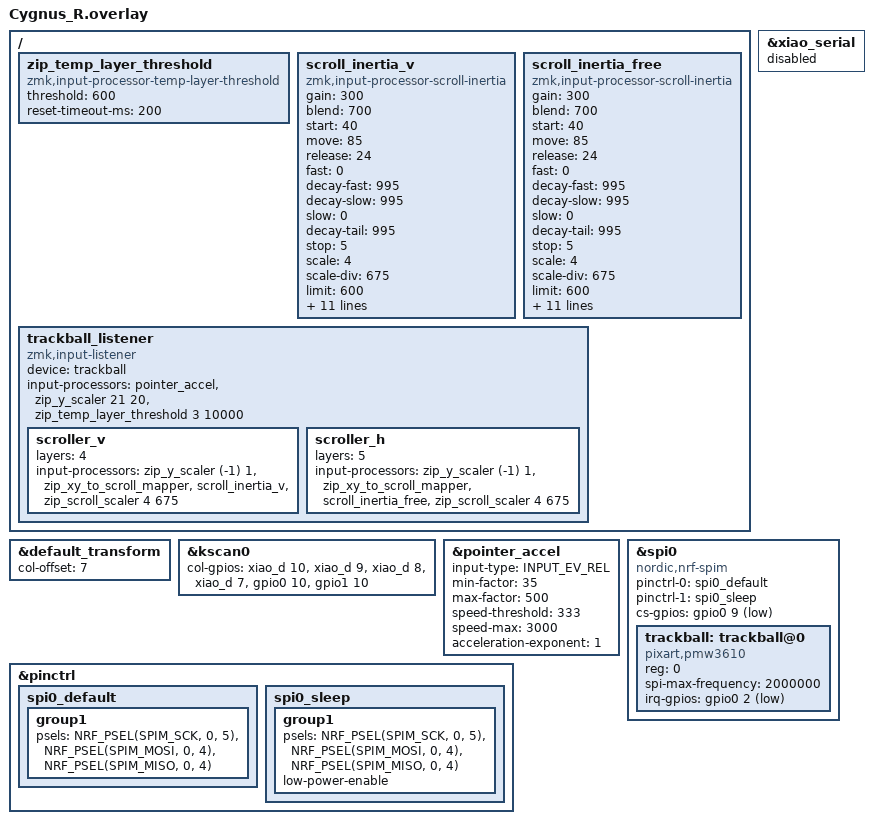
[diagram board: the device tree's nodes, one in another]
#include "Cygnus.dtsi"
#include <input/processors.dtsi>
#include <behaviors/input_gestures_accel.dtsi>
#include <dt-bindings/input/input-event-codes.h>
#include <dt-bindings/zmk/modifiers.h>

&default_transform {
    col-offset = <7>;
};

&kscan0 {
        col-gpios
            = <&xiao_d 10 GPIO_ACTIVE_HIGH>
            , <&xiao_d 9 GPIO_ACTIVE_HIGH>
            , <&xiao_d 8 GPIO_ACTIVE_HIGH>
            , <&xiao_d 7 GPIO_ACTIVE_HIGH>
            , <&gpio0 10 GPIO_ACTIVE_HIGH>
            , <&gpio1 10 GPIO_ACTIVE_HIGH>
            ;
};

/ {
    zip_temp_layer_threshold: zip_temp_layer_threshold {
        compatible = "zmk,input-processor-temp-layer-threshold";
        #input-processor-cells = <2>;
        threshold = <600>;         /* 約1/5回転 (25mm球, 1000CPI) */
        reset-timeout-ms = <200>;  /* 動きが止まったらカウントリセット */
    };

    scroll_inertia_v: scroll_inertia_v {
        compatible = "zmk,input-processor-scroll-inertia";
        #input-processor-cells = <0>;
        gain     = <300>;
        blend    = <700>;
        /* start    = <65>;          発動に必要な速度 */
        /* move     = <85>;         発動に必要な移動量 */
        start    = <40>;          /* 発動に必要な速度 */
        move     = <85>;         /* 発動に必要な移動量 */
        release  = <24>;
        fast     = <0>;
        decay-fast = <995>;
        decay-slow = <995>;
        slow     = <0>;          /* 低速区間に切替 */
        decay-tail = <995>;       /* 終端を更に緩やかに */
        stop     = <5>;           /* 離散化が目立たない閾値で停止 */
        scale    = <4>;
        scale-div = <675>;
        limit    = <600>;
        span     = <6000>;
        tick     = <4>;
        min-events = <20>;
        decel-samples = <6>;
        suppress-limit = <100>;
        peak-decay = <995>;
        axis     = <1>;
        layer    = <4>;
        friction = <10>;
        swap-mod = <(MOD_LSFT|MOD_RSFT)>;  /* Shiftで縦↔横入れ替え */
        unlock-mod = <MOD_LALT>;           /* 左Altで両軸フリー (2Dスクロール) */
    };

    scroll_inertia_free: scroll_inertia_free {
        compatible = "zmk,input-processor-scroll-inertia";
        #input-processor-cells = <0>;
        gain     = <300>;
        blend    = <700>;
        /* start    = <65>;          発動に必要な速度 */
        /* move     = <85>;         発動に必要な移動量*/
        start    = <40>;          /* 発動に必要な速度 */
        move     = <85>;         /* 発動に必要な移動量 */
        release  = <24>;
        fast     = <0>;
        decay-fast = <995>;
        decay-slow = <995>;
        slow     = <0>;          /* 低速区間に切替 */
        decay-tail = <995>;       /* 終端を更に緩やかに */
        stop     = <5>;
        scale    = <4>;
        scale-div = <675>;
        limit    = <600>;
        span     = <6000>;
        tick     = <4>;
        min-events = <20>;
        decel-samples = <6>;
        suppress-limit = <100>;
        peak-decay = <995>;
        axis     = <0>;
        layer    = <5>;
        friction = <10>;
        swap-mod = <(MOD_LSFT|MOD_RSFT)>;
        unlock-mod = <MOD_LALT>;
    };

    trackball_listener: trackball_listener {
        compatible = "zmk,input-listener";
        device = <&trackball>;
        input-processors = <
            &pointer_accel
            &zip_y_scaler 21 20
            &zip_temp_layer_threshold 3 10000
        >;

        scroller_v {
            layers = <4>;
            input-processors = <
                &zip_y_scaler (-1) 1
                &zip_xy_to_scroll_mapper
                &scroll_inertia_v
                &zip_scroll_scaler 4 675
            >;
        };

        scroller_h {
            layers = <5>;
            input-processors = <
                &zip_y_scaler (-1) 1
                &zip_xy_to_scroll_mapper
                &scroll_inertia_free
                &zip_scroll_scaler 4 675
            >;
        };
    };
};

&pointer_accel {
    input-type = <INPUT_EV_REL>;
    min-factor = <35>;             /* 開始速度: 初速を1/3に抑制 */
    max-factor = <500>;            /* 最大速度: 加速の勢いを緩める */
    speed-threshold = <333>;       /* 加速開始点 */
    speed-max = <3000>;            /* この速度で最大に到達 */
    acceleration-exponent = <1>;   /* 二次曲線 (低速は緩く、高速で伸びる) */
};

&xiao_serial { status = "disabled"; };

&pinctrl {
    spi0_default: spi0_default {
        group1 {
            psels = <NRF_PSEL(SPIM_SCK, 0, 5)>,
                <NRF_PSEL(SPIM_MOSI, 0, 4)>,
                <NRF_PSEL(SPIM_MISO, 0, 4)>;
        };
    };

    spi0_sleep: spi0_sleep {
        group1 {
            psels = <NRF_PSEL(SPIM_SCK, 0, 5)>,
                <NRF_PSEL(SPIM_MOSI, 0, 4)>,
                <NRF_PSEL(SPIM_MISO, 0, 4)>;
            low-power-enable;
        };
    };
};

&spi0 {
    status = "okay";
    compatible = "nordic,nrf-spim";
    pinctrl-0 = <&spi0_default>;
    pinctrl-1 = <&spi0_sleep>;
    pinctrl-names = "default", "sleep";
    cs-gpios = <&gpio0 9 GPIO_ACTIVE_LOW>;

    trackball: trackball@0 {
        status = "okay";
        compatible = "pixart,pmw3610";
        reg = <0>;
        spi-max-frequency = <2000000>;
        irq-gpios = <&gpio0 2 (GPIO_ACTIVE_LOW | GPIO_PULL_UP)>;
    };
};
